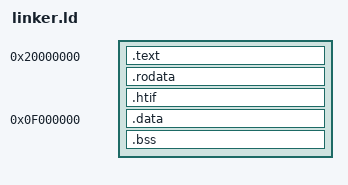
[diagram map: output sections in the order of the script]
ENTRY(_start)

SECTIONS {
  . = 0x20000000;
  .text : {
    *(entry)
    *(.text*)
  }
  etext = .;
  _etext = .;
  .rodata : {
    *(.rodata*)
  }
  .htif : {
    PROVIDE(__htif_base = . );
    *(.htif)
  }
  . = 0x0f000000;
  .data : {
    *(.data)
  }
  edata = .;
  _data = .;
  .bss : {
	_bss_start = .;
    *(.bss*)
    *(.sbss*)
    *(.scommon)
  }
  _stack_top = ALIGN(0x1000);
  . = _stack_top + 0x8000;
  _stack_pointer = .;
  end = .;
  _end = .;
  _heap_start = ALIGN(0x1000);
}
